VERSION ""

NS_ :

BS_:

BU_:

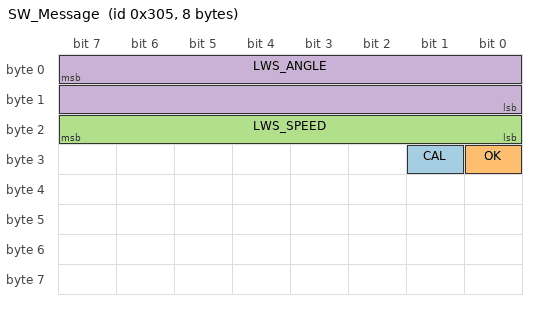
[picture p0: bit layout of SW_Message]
BO_ 773 SW_Message: 8 Vector__XXX
 SG_ CAL : 25|1@1- (1,0) [0|0] "" Vector__XXX
 SG_ OK : 24|1@0- (1,0) [0|0] "" Vector__XXX
 SG_ LWS_SPEED : 23|8@0+ (4,0) [0|1020] "deg/s" Vector__XXX
 SG_ LWS_ANGLE : 7|16@0- (0.1308,0) [-4286.0544|4285.9236] "deg" Vector__XXX

BA_DEF_  "BusType" STRING ;
BA_DEF_DEF_  "BusType" "CAN";
